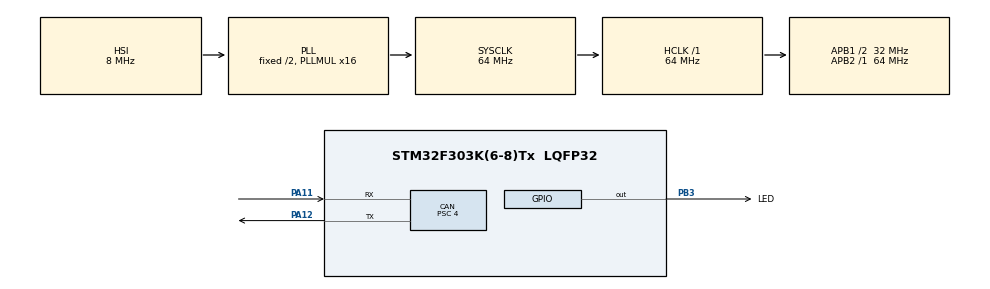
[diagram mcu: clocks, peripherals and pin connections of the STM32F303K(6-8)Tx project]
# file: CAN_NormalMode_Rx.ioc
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CAN.BS1=CAN_BS1_13TQ
CAN.BS2=CAN_BS2_2TQ
CAN.CalculateBaudRate=500000
CAN.CalculateTimeBit=2000
CAN.CalculateTimeQuantum=125.0
CAN.Prescaler=4
Mcu.Family=STM32F3
Mcu.Name=STM32F303K(6-8)Tx
Mcu.Package=LQFP32
NVIC.CAN_RX0_IRQn=true\:0\:0\:false\:false\:true\:true\:true\:true
NVIC.PriorityGroup=NVIC_PRIORITYGROUP_4
PA11.Mode=CAN_Activate
PA11.Signal=CAN_RX
PA12.Mode=CAN_Activate
PA12.Signal=CAN_TX
PA13.Mode=Serial_Wire
PA13.Signal=SYS_JTMS-SWDIO
PA14.Mode=Serial_Wire
PA14.Signal=SYS_JTCK-SWCLK
PB3.GPIO_Label=LED
PB3.Signal=GPIO_Output
ProjectManager.HeapSize=0x200
ProjectManager.StackSize=0x400
ProjectManager.TargetToolchain=STM32CubeIDE
RCC.AHBFreq_Value=64000000
RCC.APB1CLKDivider=RCC_HCLK_DIV2
RCC.APB1Freq_Value=32000000
RCC.APB1TimFreq_Value=64000000
RCC.APB2Freq_Value=64000000
RCC.APB2TimFreq_Value=64000000
RCC.CortexFreq_Value=64000000
RCC.HCLKFreq_Value=64000000
RCC.HSE_VALUE=8000000
RCC.HSI_VALUE=8000000
RCC.PLLMUL=RCC_PLL_MUL16
RCC.SYSCLKFreq_VALUE=64000000
RCC.SYSCLKSourceVirtual=RCC_SYSCLKSOURCE_PLLCLK
board=custom

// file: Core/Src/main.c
/* USER CODE BEGIN Header */
/**
  ******************************************************************************
  * @file           : main.c
  * @brief          : Main program body
  ******************************************************************************
  * @attention
  *
  * Copyright (c) 2023 STMicroelectronics.
  * All rights reserved.
  *
  * This software is licensed under terms that can be found in the LICENSE file
  * in the root directory of this software component.
  * If no LICENSE file comes with this software, it is provided AS-IS.
  *
  ******************************************************************************
  */
/* USER CODE END Header */
#include "main.h"

CAN_HandleTypeDef hcan;

void SystemClock_Config(void);
static void MX_GPIO_Init(void);
static void MX_CAN_Init(void);

/* USER CODE BEGIN 0 */
CAN_RxHeaderTypeDef RxHeader;

uint8_t RxData[8];

uint8_t flag = 0;

void HAL_CAN_RxFifo0MsgPendingCallback(CAN_HandleTypeDef *hcan)
{
	HAL_CAN_GetRxMessage(hcan, CAN_RX_FIFO0, &RxHeader, RxData);

	if(RxData[0] ==4&& RxData[1] == 200){
		flag = 1;
	}
}
/* USER CODE END 0 */

int main(void)
{

  /* MCU Configuration--------------------------------------------------------*/

  /* Reset of all peripherals, Initializes the Flash interface and the Systick. */
  HAL_Init();

  /* Configure the system clock */
  SystemClock_Config();

  /* Initialize all configured peripherals */
  MX_GPIO_Init();
  MX_CAN_Init();
  /* USER CODE BEGIN 2 */
  HAL_CAN_Start(&hcan);

  HAL_CAN_ActivateNotification(&hcan, CAN_IT_RX_FIFO0_MSG_PENDING);
  /* USER CODE END 2 */

  /* Infinite loop */
  /* USER CODE BEGIN WHILE */
  while (1)
  {
	if(flag){
		for(uint8_t i = 0; i < RxData[0]; i++){
			HAL_GPIO_TogglePin(LED_GPIO_Port, LED_Pin);
			HAL_Delay(RxData[1]);
		}

		flag = 0;
	}
    /* USER CODE END WHILE */

  }
}

void SystemClock_Config(void)
{
  RCC_OscInitTypeDef RCC_OscInitStruct = {0};
  RCC_ClkInitTypeDef RCC_ClkInitStruct = {0};

  /** Initializes the RCC Oscillators according to the specified parameters
  * in the RCC_OscInitTypeDef structure.
  */
  RCC_OscInitStruct.OscillatorType = RCC_OSCILLATORTYPE_HSI;
  RCC_OscInitStruct.HSIState = RCC_HSI_ON;
  RCC_OscInitStruct.HSICalibrationValue = RCC_HSICALIBRATION_DEFAULT;
  RCC_OscInitStruct.PLL.PLLState = RCC_PLL_ON;
  RCC_OscInitStruct.PLL.PLLSource = RCC_PLLSOURCE_HSI;
  RCC_OscInitStruct.PLL.PLLMUL = RCC_PLL_MUL16;
  if (HAL_RCC_OscConfig(&RCC_OscInitStruct) != HAL_OK)
  {
    Error_Handler();
  }

  /** Initializes the CPU, AHB and APB buses clocks
  */
  RCC_ClkInitStruct.ClockType = RCC_CLOCKTYPE_HCLK|RCC_CLOCKTYPE_SYSCLK
                              |RCC_CLOCKTYPE_PCLK1|RCC_CLOCKTYPE_PCLK2;
  RCC_ClkInitStruct.SYSCLKSource = RCC_SYSCLKSOURCE_PLLCLK;
  RCC_ClkInitStruct.AHBCLKDivider = RCC_SYSCLK_DIV1;
  RCC_ClkInitStruct.APB1CLKDivider = RCC_HCLK_DIV2;
  RCC_ClkInitStruct.APB2CLKDivider = RCC_HCLK_DIV1;

  if (HAL_RCC_ClockConfig(&RCC_ClkInitStruct, FLASH_LATENCY_2) != HAL_OK)
  {
    Error_Handler();
  }
}

static void MX_CAN_Init(void)
{

  hcan.Instance = CAN;
  hcan.Init.Prescaler = 4;
  hcan.Init.Mode = CAN_MODE_NORMAL;
  hcan.Init.SyncJumpWidth = CAN_SJW_1TQ;
  hcan.Init.TimeSeg1 = CAN_BS1_13TQ;
  hcan.Init.TimeSeg2 = CAN_BS2_2TQ;
  hcan.Init.TimeTriggeredMode = DISABLE;
  hcan.Init.AutoBusOff = DISABLE;
  hcan.Init.AutoWakeUp = DISABLE;
  hcan.Init.AutoRetransmission = DISABLE;
  hcan.Init.ReceiveFifoLocked = DISABLE;
  hcan.Init.TransmitFifoPriority = DISABLE;
  if (HAL_CAN_Init(&hcan) != HAL_OK)
  {
    Error_Handler();
  }
  /* USER CODE BEGIN CAN_Init 2 */
  CAN_FilterTypeDef canfilterconfig;

  canfilterconfig.FilterActivation = CAN_FILTER_ENABLE;
  canfilterconfig.FilterBank = 10;
  canfilterconfig.FilterFIFOAssignment = CAN_FILTER_FIFO0;
  canfilterconfig.FilterIdHigh = 0x303<<5;
  canfilterconfig.FilterIdLow = 0x0000;
  canfilterconfig.FilterMaskIdHigh = 0x303<<5;
  canfilterconfig.FilterMaskIdLow = 0x0000;
  canfilterconfig.FilterMode = CAN_FILTERMODE_IDMASK;
  canfilterconfig.FilterScale = CAN_FILTERSCALE_32BIT;
  canfilterconfig.SlaveStartFilterBank = 0;

  HAL_CAN_ConfigFilter(&hcan,&canfilterconfig);
  /* USER CODE END CAN_Init 2 */

}

static void MX_GPIO_Init(void)
{
  GPIO_InitTypeDef GPIO_InitStruct = {0};

  /* GPIO Ports Clock Enable */
  __HAL_RCC_GPIOA_CLK_ENABLE();
  __HAL_RCC_GPIOB_CLK_ENABLE();

  /*Configure GPIO pin Output Level */
  HAL_GPIO_WritePin(LED_GPIO_Port, LED_Pin, GPIO_PIN_RESET);

  /*Configure GPIO pin : LED_Pin */
  GPIO_InitStruct.Pin = LED_Pin;
  GPIO_InitStruct.Mode = GPIO_MODE_OUTPUT_PP;
  GPIO_InitStruct.Pull = GPIO_NOPULL;
  GPIO_InitStruct.Speed = GPIO_SPEED_FREQ_LOW;
  HAL_GPIO_Init(LED_GPIO_Port, &GPIO_InitStruct);

}

void Error_Handler(void)
{
  __disable_irq();
  while (1)
  {
  }
}
